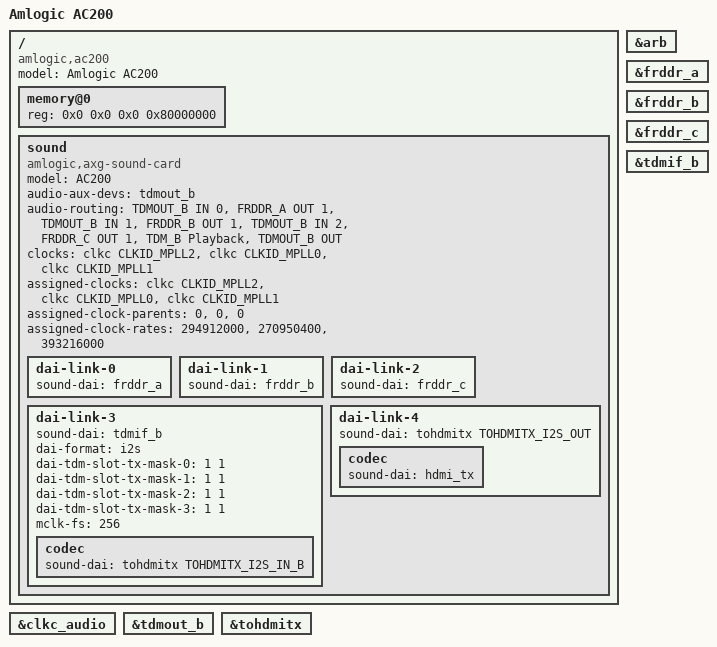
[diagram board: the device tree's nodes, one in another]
// SPDX-License-Identifier: (GPL-2.0+ OR MIT)
/*
 * Copyright (c) 2024, SaluteDevices. All Rights Reserved.
 */

/dts-v1/;

#include "meson-sm1-ac2xx.dtsi"
#include <dt-bindings/sound/meson-g12a-tohdmitx.h>

/ {
	compatible = "amlogic,ac200", "amlogic,sm1";
	model = "Amlogic AC200";

	memory@0 {
		device_type = "memory";
		reg = <0x0 0x0 0x0 0x80000000>; /* 2 GiB */
	};

	sound {
		compatible = "amlogic,axg-sound-card";
		model = "AC200";
		audio-aux-devs = <&tdmout_b>;
		audio-routing = "TDMOUT_B IN 0", "FRDDR_A OUT 1",
				"TDMOUT_B IN 1", "FRDDR_B OUT 1",
				"TDMOUT_B IN 2", "FRDDR_C OUT 1",
				"TDM_B Playback", "TDMOUT_B OUT";

		clocks = <&clkc CLKID_MPLL2>,
			 <&clkc CLKID_MPLL0>,
			 <&clkc CLKID_MPLL1>;

		assigned-clocks = <&clkc CLKID_MPLL2>,
				  <&clkc CLKID_MPLL0>,
				  <&clkc CLKID_MPLL1>;
		assigned-clock-parents = <0>, <0>, <0>;
		assigned-clock-rates = <294912000>,
				       <270950400>,
				       <393216000>;

		dai-link-0 {
			sound-dai = <&frddr_a>;
		};

		dai-link-1 {
			sound-dai = <&frddr_b>;
		};

		dai-link-2 {
			sound-dai = <&frddr_c>;
		};

		/* 8ch hdmi interface */
		dai-link-3 {
			sound-dai = <&tdmif_b>;
			dai-format = "i2s";
			dai-tdm-slot-tx-mask-0 = <1 1>;
			dai-tdm-slot-tx-mask-1 = <1 1>;
			dai-tdm-slot-tx-mask-2 = <1 1>;
			dai-tdm-slot-tx-mask-3 = <1 1>;
			mclk-fs = <256>;

			codec {
				sound-dai = <&tohdmitx TOHDMITX_I2S_IN_B>;
			};
		};

		/* hdmi glue */
		dai-link-4 {
			sound-dai = <&tohdmitx TOHDMITX_I2S_OUT>;

			codec {
				sound-dai = <&hdmi_tx>;
			};
		};
	};
};

&clkc_audio {
	status = "okay";
};

&arb {
	status = "okay";
};

&frddr_a {
	status = "okay";
};

&frddr_b {
	status = "okay";
};

&frddr_c {
	status = "okay";
};

&tdmif_b {
	status = "okay";
};

&tdmout_b {
	status = "okay";
};

&tohdmitx {
	status = "okay";
};
